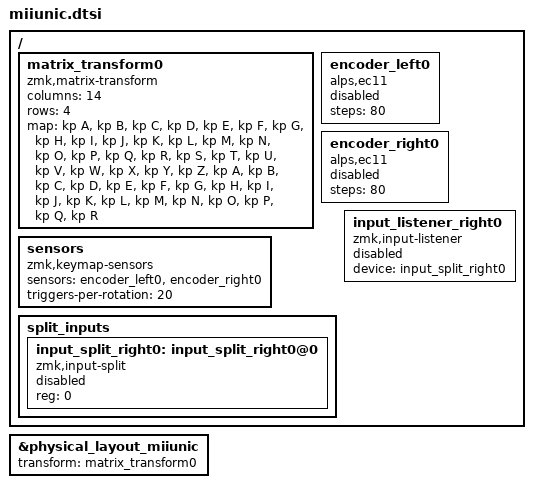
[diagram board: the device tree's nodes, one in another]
#include "miiunic-layouts.dtsi"
#include <dt-bindings/zmk/matrix_transform.h>

/ {
    matrix_transform0: matrix_transform0 {
        compatible = "zmk,matrix-transform";
        columns = <14>;
        rows = <4>;
        map = <
&kp A  &kp B  &kp C  &kp D  &kp E  &kp F                &kp G  &kp H  &kp I  &kp J  &kp K  &kp L
&kp M  &kp N  &kp O  &kp P  &kp Q  &kp R                &kp S  &kp T  &kp U  &kp V  &kp W  &kp X
&kp Y  &kp Z  &kp A  &kp B  &kp C  &kp D                &kp E  &kp F  &kp G  &kp H  &kp I  &kp J
                     &kp K  &kp L  &kp M  &kp N  &kp O  &kp P  &kp Q  &kp R
        >;
    };
};

&physical_layout_miiunic {
    transform = <&matrix_transform0>;
};

// Encoders for all parts of the keyboard.
// If the encoder(s) are not behaving as expected,
// update steps and triggers-per-rotation to match your hardware.
// All pin assignments are done in the part overlays.

/ {
    encoder_left0: encoder_left0 {
        compatible = "alps,ec11";
        steps = <80>;
        status = "disabled";
    };
    encoder_right0: encoder_right0 {
        compatible = "alps,ec11";
        steps = <80>;
        status = "disabled";
    };

    sensors: sensors {
        compatible = "zmk,keymap-sensors";
        sensors = <&encoder_left0 &encoder_right0>;
        triggers-per-rotation = <20>;
    };
};

// Input devices
/ {
    split_inputs {
        #address-cells = <1>;
        #size-cells = <0>;

        input_split_right0: input_split_right0@0 {
            compatible = "zmk,input-split";
            reg = <0>;
            status = "disabled";
        };
    };

    input_listener_right0: input_listener_right0 {
        compatible = "zmk,input-listener";
        status = "disabled";
        device = <&input_split_right0>;
    };
};

